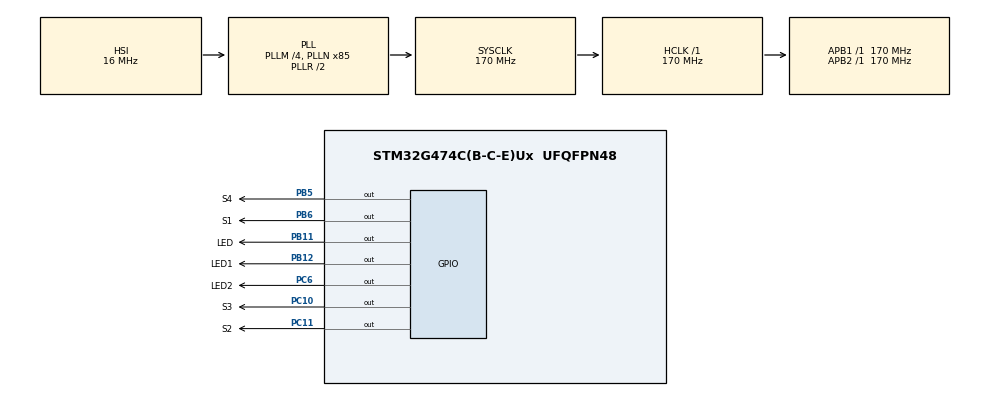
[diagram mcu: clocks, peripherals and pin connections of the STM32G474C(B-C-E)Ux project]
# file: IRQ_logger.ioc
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Mcu.Family=STM32G4
Mcu.Name=STM32G474C(B-C-E)Ux
Mcu.Package=UFQFPN48
NVIC.PriorityGroup=NVIC_PRIORITYGROUP_4
NVIC.TIM1_TRG_COM_TIM17_IRQn=true\:0\:0\:false\:false\:true\:true\:true
NVIC.TIM1_UP_TIM16_IRQn=true\:0\:0\:false\:false\:true\:true\:true
NVIC.TIM6_DAC_IRQn=true\:1\:0\:true\:false\:true\:true\:true
NVIC.TIM7_DAC_IRQn=true\:2\:0\:true\:false\:true\:true\:true
PA13.Mode=Serial_Wire
PA13.Signal=SYS_JTMS-SWDIO
PA14.Mode=Serial_Wire
PA14.Signal=SYS_JTCK-SWCLK
PB11.GPIO_Label=LED
PB11.Signal=GPIO_Output
PB12.GPIO_Label=LED1
PB12.Signal=GPIO_Output
PB5.GPIO_Label=S4
PB5.Signal=GPIO_Output
PB6.GPIO_Label=S1
PB6.Signal=GPIO_Output
PC10.GPIO_Label=S3
PC10.Signal=GPIO_Output
PC11.GPIO_Label=S2
PC11.Signal=GPIO_Output
PC6.GPIO_Label=LED2
PC6.Signal=GPIO_Output
ProjectManager.HeapSize=0x200
ProjectManager.StackSize=0x400
ProjectManager.TargetToolchain=STM32CubeIDE
RCC.ADC12Freq_Value=170000000
RCC.ADC345Freq_Value=170000000
RCC.AHBFreq_Value=170000000
RCC.APB1Freq_Value=170000000
RCC.APB1TimFreq_Value=170000000
RCC.APB2Freq_Value=170000000
RCC.APB2TimFreq_Value=170000000
RCC.CortexFreq_Value=170000000
RCC.EXTERNAL_CLOCK_VALUE=12288000
RCC.HCLKFreq_Value=170000000
RCC.HSE_VALUE=8000000
RCC.HSI48_VALUE=48000000
RCC.HSI_VALUE=16000000
RCC.LSE_VALUE=32768
RCC.PLLM=RCC_PLLM_DIV4
RCC.PLLN=85
RCC.SYSCLKFreq_VALUE=170000000
RCC.SYSCLKSource=RCC_SYSCLKSOURCE_PLLCLK
RCC.USBFreq_Value=170000000
RCC.VCOOutputFreq_Value=340000000
TIM16.PeriodNoDither=5999
TIM16.Prescaler=169
TIM17.PeriodNoDither=999
TIM17.Prescaler=169
TIM6.PeriodNoDither=1999
TIM6.Prescaler=169
TIM7.PeriodNoDither=999
TIM7.Prescaler=169
VP_SYS_VS_DBSignals.Mode=DisableDeadBatterySignals
VP_TIM16_VS_ClockSourceINT.Mode=Enable_Timer
VP_TIM17_VS_ClockSourceINT.Mode=Enable_Timer
VP_TIM6_VS_ClockSourceINT.Mode=Enable_Timer
VP_TIM7_VS_ClockSourceINT.Mode=Enable_Timer
board=custom

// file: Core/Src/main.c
/* USER CODE BEGIN Header */
/**
  ******************************************************************************
  * @file           : main.c
  * @brief          : Main program body
  ******************************************************************************
  * @attention
  *
  * Copyright (c) 2022 STMicroelectronics.
  * All rights reserved.
  *
  * This software is licensed under terms that can be found in the LICENSE file
  * in the root directory of this software component.
  * If no LICENSE file comes with this software, it is provided AS-IS.
  *
  ******************************************************************************
  */
/* USER CODE END Header */
#include "main.h"

/* USER CODE BEGIN Includes */
#include "IRQ_logger.h"
/* USER CODE END Includes */

void SystemClock_Config(void);
static void MX_GPIO_Init(void);
static void MX_TIM6_Init(void);
static void MX_TIM7_Init(void);
static void MX_TIM16_Init(void);
static void MX_TIM17_Init(void);

int main(void)
{

  /* MCU Configuration--------------------------------------------------------*/

  /* Reset of all peripherals, Initializes the Flash interface and the Systick. */
  HAL_Init();

  /* Configure the system clock */
  SystemClock_Config();

  /* Initialize all configured peripherals */
  MX_GPIO_Init();
  MX_TIM6_Init();
  MX_TIM7_Init();
  MX_TIM16_Init();
  MX_TIM17_Init();
  /* USER CODE BEGIN 2 */
  dbg_init();

  LL_TIM_EnableIT_UPDATE(TIM6);
  LL_TIM_EnableIT_UPDATE(TIM7);
  LL_TIM_EnableIT_UPDATE(TIM16);

  LL_TIM_EnableCounter(TIM6);
  LL_TIM_EnableCounter(TIM7);
  LL_TIM_EnableCounter(TIM16);

  /* USER CODE END 2 */

  /* Infinite loop */
  while (1)
  {

  }
}

void SystemClock_Config(void)
{
  RCC_OscInitTypeDef RCC_OscInitStruct = {0};
  RCC_ClkInitTypeDef RCC_ClkInitStruct = {0};

  /** Configure the main internal regulator output voltage
  */
  HAL_PWREx_ControlVoltageScaling(PWR_REGULATOR_VOLTAGE_SCALE1_BOOST);
  /** Initializes the RCC Oscillators according to the specified parameters
  * in the RCC_OscInitTypeDef structure.
  */
  RCC_OscInitStruct.OscillatorType = RCC_OSCILLATORTYPE_HSI;
  RCC_OscInitStruct.HSIState = RCC_HSI_ON;
  RCC_OscInitStruct.HSICalibrationValue = RCC_HSICALIBRATION_DEFAULT;
  RCC_OscInitStruct.PLL.PLLState = RCC_PLL_ON;
  RCC_OscInitStruct.PLL.PLLSource = RCC_PLLSOURCE_HSI;
  RCC_OscInitStruct.PLL.PLLM = RCC_PLLM_DIV4;
  RCC_OscInitStruct.PLL.PLLN = 85;
  RCC_OscInitStruct.PLL.PLLP = RCC_PLLP_DIV2;
  RCC_OscInitStruct.PLL.PLLQ = RCC_PLLQ_DIV2;
  RCC_OscInitStruct.PLL.PLLR = RCC_PLLR_DIV2;
  if (HAL_RCC_OscConfig(&RCC_OscInitStruct) != HAL_OK)
  {
    Error_Handler();
  }
  /** Initializes the CPU, AHB and APB buses clocks
  */
  RCC_ClkInitStruct.ClockType = RCC_CLOCKTYPE_HCLK|RCC_CLOCKTYPE_SYSCLK
                              |RCC_CLOCKTYPE_PCLK1|RCC_CLOCKTYPE_PCLK2;
  RCC_ClkInitStruct.SYSCLKSource = RCC_SYSCLKSOURCE_PLLCLK;
  RCC_ClkInitStruct.AHBCLKDivider = RCC_SYSCLK_DIV1;
  RCC_ClkInitStruct.APB1CLKDivider = RCC_HCLK_DIV1;
  RCC_ClkInitStruct.APB2CLKDivider = RCC_HCLK_DIV1;

  if (HAL_RCC_ClockConfig(&RCC_ClkInitStruct, FLASH_LATENCY_4) != HAL_OK)
  {
    Error_Handler();
  }
}

static void MX_TIM6_Init(void)
{

  LL_TIM_InitTypeDef TIM_InitStruct = {0};

  /* Peripheral clock enable */
  LL_APB1_GRP1_EnableClock(LL_APB1_GRP1_PERIPH_TIM6);

  /* TIM6 interrupt Init */
  NVIC_SetPriority(TIM6_DAC_IRQn, NVIC_EncodePriority(NVIC_GetPriorityGrouping(),1, 0));
  NVIC_EnableIRQ(TIM6_DAC_IRQn);

  TIM_InitStruct.Prescaler = 169;
  TIM_InitStruct.CounterMode = LL_TIM_COUNTERMODE_UP;
  TIM_InitStruct.Autoreload = 1999;
  LL_TIM_Init(TIM6, &TIM_InitStruct);
  LL_TIM_DisableARRPreload(TIM6);
  LL_TIM_SetTriggerOutput(TIM6, LL_TIM_TRGO_RESET);
  LL_TIM_DisableMasterSlaveMode(TIM6);

}

static void MX_TIM7_Init(void)
{

  LL_TIM_InitTypeDef TIM_InitStruct = {0};

  /* Peripheral clock enable */
  LL_APB1_GRP1_EnableClock(LL_APB1_GRP1_PERIPH_TIM7);

  /* TIM7 interrupt Init */
  NVIC_SetPriority(TIM7_DAC_IRQn, NVIC_EncodePriority(NVIC_GetPriorityGrouping(),2, 0));
  NVIC_EnableIRQ(TIM7_DAC_IRQn);

  TIM_InitStruct.Prescaler = 169;
  TIM_InitStruct.CounterMode = LL_TIM_COUNTERMODE_UP;
  TIM_InitStruct.Autoreload = 999;
  LL_TIM_Init(TIM7, &TIM_InitStruct);
  LL_TIM_DisableARRPreload(TIM7);
  LL_TIM_SetTriggerOutput(TIM7, LL_TIM_TRGO_RESET);
  LL_TIM_DisableMasterSlaveMode(TIM7);

}

static void MX_TIM16_Init(void)
{

  LL_TIM_InitTypeDef TIM_InitStruct = {0};

  /* Peripheral clock enable */
  LL_APB2_GRP1_EnableClock(LL_APB2_GRP1_PERIPH_TIM16);

  /* TIM16 interrupt Init */
  NVIC_SetPriority(TIM1_UP_TIM16_IRQn, NVIC_EncodePriority(NVIC_GetPriorityGrouping(),0, 0));
  NVIC_EnableIRQ(TIM1_UP_TIM16_IRQn);

  TIM_InitStruct.Prescaler = 169;
  TIM_InitStruct.CounterMode = LL_TIM_COUNTERMODE_UP;
  TIM_InitStruct.Autoreload = 5999;
  TIM_InitStruct.ClockDivision = LL_TIM_CLOCKDIVISION_DIV1;
  TIM_InitStruct.RepetitionCounter = 0;
  LL_TIM_Init(TIM16, &TIM_InitStruct);
  LL_TIM_DisableARRPreload(TIM16);

}

static void MX_TIM17_Init(void)
{

  LL_TIM_InitTypeDef TIM_InitStruct = {0};

  /* Peripheral clock enable */
  LL_APB2_GRP1_EnableClock(LL_APB2_GRP1_PERIPH_TIM17);

  /* TIM17 interrupt Init */
  NVIC_SetPriority(TIM1_TRG_COM_TIM17_IRQn, NVIC_EncodePriority(NVIC_GetPriorityGrouping(),0, 0));
  NVIC_EnableIRQ(TIM1_TRG_COM_TIM17_IRQn);

  TIM_InitStruct.Prescaler = 169;
  TIM_InitStruct.CounterMode = LL_TIM_COUNTERMODE_UP;
  TIM_InitStruct.Autoreload = 999;
  TIM_InitStruct.ClockDivision = LL_TIM_CLOCKDIVISION_DIV1;
  TIM_InitStruct.RepetitionCounter = 0;
  LL_TIM_Init(TIM17, &TIM_InitStruct);
  LL_TIM_DisableARRPreload(TIM17);

}

static void MX_GPIO_Init(void)
{
  GPIO_InitTypeDef GPIO_InitStruct = {0};

  /* GPIO Ports Clock Enable */
  __HAL_RCC_GPIOB_CLK_ENABLE();
  __HAL_RCC_GPIOC_CLK_ENABLE();
  __HAL_RCC_GPIOA_CLK_ENABLE();

  /*Configure GPIO pin Output Level */
  HAL_GPIO_WritePin(GPIOB, LED_Pin|LED1_Pin|S4_Pin|S1_Pin, GPIO_PIN_RESET);

  /*Configure GPIO pin Output Level */
  HAL_GPIO_WritePin(GPIOC, LED2_Pin|S3_Pin|S2_Pin, GPIO_PIN_RESET);

  /*Configure GPIO pins : LED_Pin LED1_Pin S4_Pin S1_Pin */
  GPIO_InitStruct.Pin = LED_Pin|LED1_Pin|S4_Pin|S1_Pin;
  GPIO_InitStruct.Mode = GPIO_MODE_OUTPUT_PP;
  GPIO_InitStruct.Pull = GPIO_NOPULL;
  GPIO_InitStruct.Speed = GPIO_SPEED_FREQ_LOW;
  HAL_GPIO_Init(GPIOB, &GPIO_InitStruct);

  /*Configure GPIO pins : LED2_Pin S3_Pin S2_Pin */
  GPIO_InitStruct.Pin = LED2_Pin|S3_Pin|S2_Pin;
  GPIO_InitStruct.Mode = GPIO_MODE_OUTPUT_PP;
  GPIO_InitStruct.Pull = GPIO_NOPULL;
  GPIO_InitStruct.Speed = GPIO_SPEED_FREQ_LOW;
  HAL_GPIO_Init(GPIOC, &GPIO_InitStruct);

}

void Error_Handler(void)
{
  __disable_irq();
  while (1)
  {
  }
}
